# PIC32MZ1025W104132 register map
Vendor: Microchip
Registers are 32-bit, read-write, no defined reset value unless marked. A register's access mark holds for its fields unless they carry their own. Addresses are absolute, and some are shared; only a register's first bit layout is shown; [hi:lo] are bit positions; {n}, {i} and the like mark numbered series; 'fields as' and 'values as' point back to an identical list.

## ICAP1
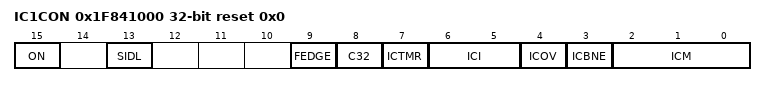
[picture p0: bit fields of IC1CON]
0x1F841000 IC1CON reset 0x0
  [15] ON, [13] SIDL, [9] FEDGE, [8] C32, [7] ICTMR, [6:5] ICI, [4] ICOV ro, [3] ICBNE ro, [2:0] ICM
0x1F841010 IC1BUF ro — (power-on value xxxxxxxxxxxxxxxxxxxxxxxxxxxxxxxx)

## ICAP2
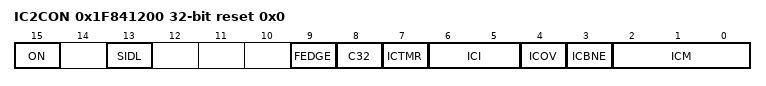
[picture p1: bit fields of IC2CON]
0x1F841200 IC2CON reset 0x0
  [15] ON, [13] SIDL, [9] FEDGE, [8] C32, [7] ICTMR, [6:5] ICI, [4] ICOV ro, [3] ICBNE ro, [2:0] ICM
0x1F841210 IC2BUF ro — (power-on value xxxxxxxxxxxxxxxxxxxxxxxxxxxxxxxx)

## ICAP3
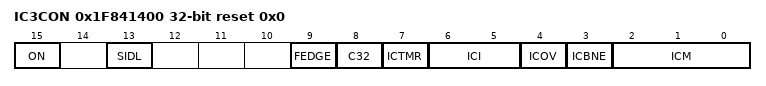
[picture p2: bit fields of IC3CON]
0x1F841400 IC3CON reset 0x0
  [15] ON, [13] SIDL, [9] FEDGE, [8] C32, [7] ICTMR, [6:5] ICI, [4] ICOV ro, [3] ICBNE ro, [2:0] ICM
0x1F841410 IC3BUF ro — (power-on value xxxxxxxxxxxxxxxxxxxxxxxxxxxxxxxx)

## ICAP4
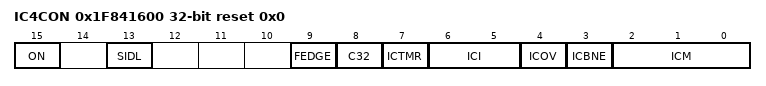
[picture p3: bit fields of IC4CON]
0x1F841600 IC4CON reset 0x0
  [15] ON, [13] SIDL, [9] FEDGE, [8] C32, [7] ICTMR, [6:5] ICI, [4] ICOV ro, [3] ICBNE ro, [2:0] ICM
0x1F841610 IC4BUF ro — (power-on value xxxxxxxxxxxxxxxxxxxxxxxxxxxxxxxx)

## OCMP1
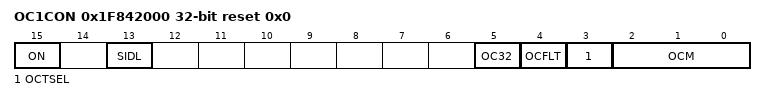
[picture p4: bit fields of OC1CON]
0x1F842000 OC1CON reset 0x0
  [15] ON, [13] SIDL, [5] OC32, [4] OCFLT ro, [3] OCTSEL, [2:0] OCM
0x1F842010 OC1R — (power-on value xxxxxxxxxxxxxxxxxxxxxxxxxxxxxxxx)
0x1F842020 OC1RS — (power-on value xxxxxxxxxxxxxxxxxxxxxxxxxxxxxxxx)

## OCMP2
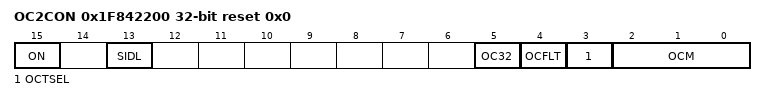
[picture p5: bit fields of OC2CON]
0x1F842200 OC2CON reset 0x0
  [15] ON, [13] SIDL, [5] OC32, [4] OCFLT ro, [3] OCTSEL, [2:0] OCM
0x1F842210 OC2R — (power-on value xxxxxxxxxxxxxxxxxxxxxxxxxxxxxxxx)
0x1F842220 OC2RS — (power-on value xxxxxxxxxxxxxxxxxxxxxxxxxxxxxxxx)

## OCMP3
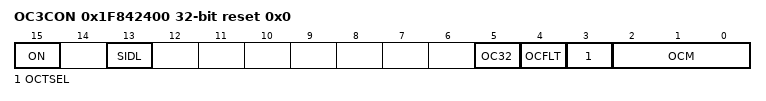
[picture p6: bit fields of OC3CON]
0x1F842400 OC3CON reset 0x0
  [15] ON, [13] SIDL, [5] OC32, [4] OCFLT ro, [3] OCTSEL, [2:0] OCM
0x1F842410 OC3R — (power-on value xxxxxxxxxxxxxxxxxxxxxxxxxxxxxxxx)
0x1F842420 OC3RS — (power-on value xxxxxxxxxxxxxxxxxxxxxxxxxxxxxxxx)

## OCMP4
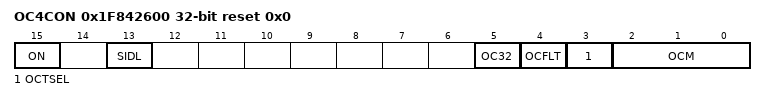
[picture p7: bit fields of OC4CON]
0x1F842600 OC4CON reset 0x0
  [15] ON, [13] SIDL, [5] OC32, [4] OCFLT ro, [3] OCTSEL, [2:0] OCM
0x1F842610 OC4R — (power-on value xxxxxxxxxxxxxxxxxxxxxxxxxxxxxxxx)
0x1F842620 OC4RS — (power-on value xxxxxxxxxxxxxxxxxxxxxxxxxxxxxxxx)

## USB1
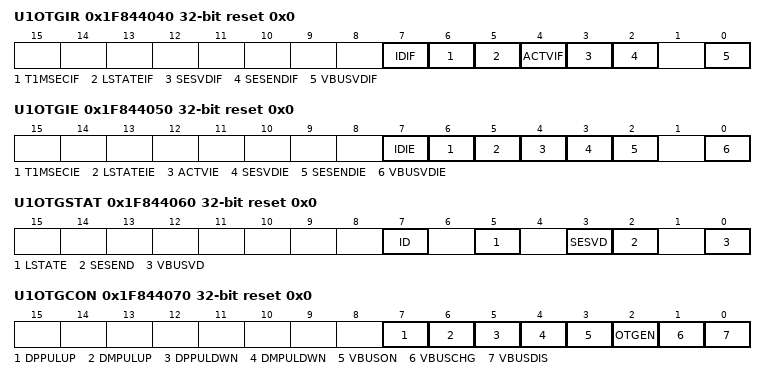
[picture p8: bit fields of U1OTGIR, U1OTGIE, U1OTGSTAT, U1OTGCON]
0x1F844040 U1OTGIR reset 0x0
  [7] IDIF, [6] T1MSECIF, [5] LSTATEIF, [4] ACTVIF, [3] SESVDIF, [2] SESENDIF, [0] VBUSVDIF
0x1F844050 U1OTGIE reset 0x0
  [7] IDIE, [6] T1MSECIE, [5] LSTATEIE, [4] ACTVIE, [3] SESVDIE, [2] SESENDIE, [0] VBUSVDIE
0x1F844060 U1OTGSTAT reset 0x0
  [7] ID, [5] LSTATE, [3] SESVD, [2] SESEND, [0] VBUSVD
0x1F844070 U1OTGCON reset 0x0
  [7] DPPULUP, [6] DMPULUP, [5] DPPULDWN, [4] DMPULDWN, [3] VBUSON, [2] OTGEN, [1] VBUSCHG, [0] VBUSDIS
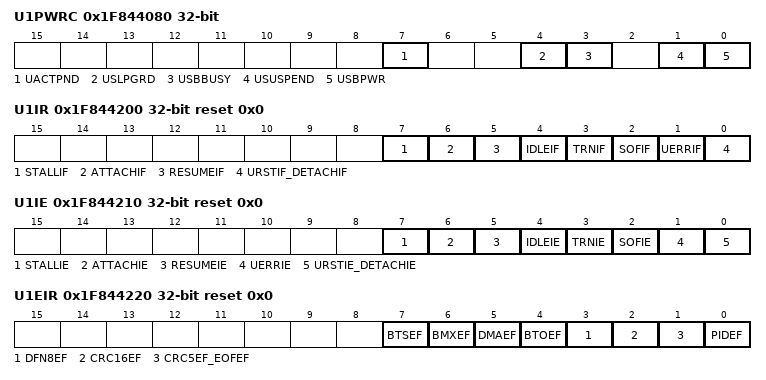
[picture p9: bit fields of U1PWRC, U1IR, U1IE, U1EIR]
0x1F844080 U1PWRC — (power-on value ------------------------0--0x-00)
  [7] UACTPND ro, [4] USLPGRD, [3] USBBUSY, [1] USUSPEND, [0] USBPWR
0x1F844200 U1IR reset 0x0
  [7] STALLIF, [6] ATTACHIF, [5] RESUMEIF, [4] IDLEIF, [3] TRNIF, [2] SOFIF, [1] UERRIF, [0] URSTIF_DETACHIF
0x1F844210 U1IE reset 0x0
  [7] STALLIE, [6] ATTACHIE, [5] RESUMEIE, [4] IDLEIE, [3] TRNIE, [2] SOFIE, [1] UERRIE, [0] URSTIE_DETACHIE
0x1F844220 U1EIR reset 0x0
  [7] BTSEF, [6] BMXEF, [5] DMAEF, [4] BTOEF, [3] DFN8EF, [2] CRC16EF, [1] CRC5EF_EOFEF, [0] PIDEF
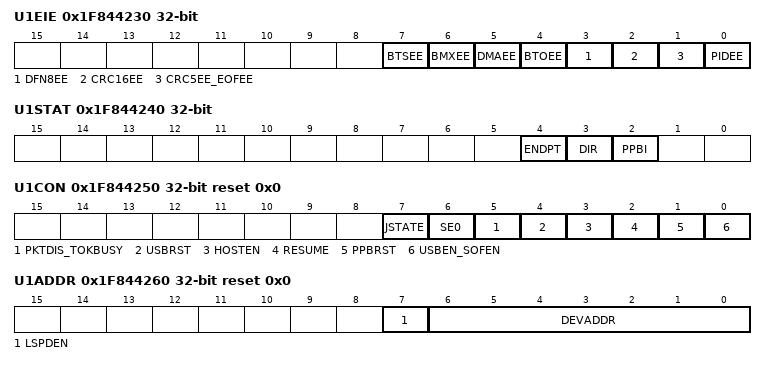
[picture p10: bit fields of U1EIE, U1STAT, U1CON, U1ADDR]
0x1F844230 U1EIE — (power-on value ------------------------0000000x)
  [7] BTSEE, [6] BMXEE, [5] DMAEE, [4] BTOEE, [3] DFN8EE, [2] CRC16EE, [1] CRC5EE_EOFEE, [0] PIDEE
0x1F844240 U1STAT ro
  [4] ENDPT, [3] DIR, [2] PPBI
0x1F844250 U1CON reset 0x0
  [7] JSTATE, [6] SE0, [5] PKTDIS_TOKBUSY, [4] USBRST, [3] HOSTEN, [2] RESUME, [1] PPBRST, [0] USBEN_SOFEN
0x1F844260 U1ADDR reset 0x0
  [7] LSPDEN, [6:0] DEVADDR
0x1F844270 U1BDTP1 reset 0x0
  [7:1] BDTPTRL
0x1F844280 U1FRML ro
  [7:0] FRML
0x1F844290 U1FRMH ro
  [2:0] FRMH
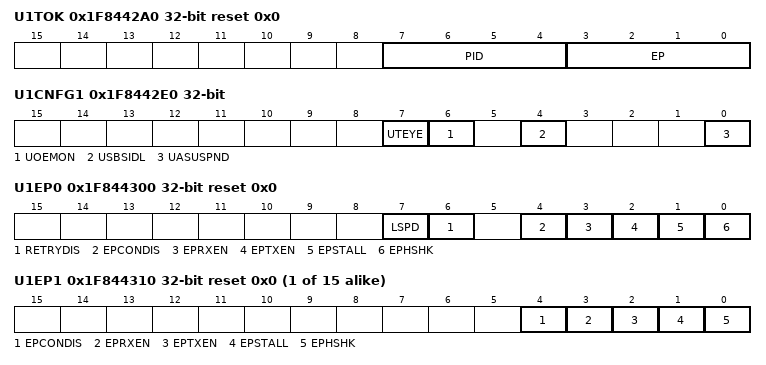
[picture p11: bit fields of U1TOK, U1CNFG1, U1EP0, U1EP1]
0x1F8442A0 U1TOK reset 0x0
  [7:4] PID, [3:0] EP
0x1F8442B0 U1SOF reset 0x0
  [7:0] CNT
0x1F8442C0 U1BDTP2 reset 0x0
  [7:0] BDTPTRH
0x1F8442D0 U1BDTP3 reset 0x0
  [7:0] BDTPTRU
0x1F8442E0 U1CNFG1 — (power-on value ------------------------xxxx-00x)
  [7] UTEYE, [6] UOEMON, [4] USBSIDL, [0] UASUSPND
0x1F844300 U1EP0 reset 0x0
  [7] LSPD, [6] RETRYDIS, [4] EPCONDIS, [3] EPRXEN, [2] EPTXEN, [1] EPSTALL, [0] EPHSHK
{0x1F844300+0x10*i} U1EP{i} reset 0x0 (i=1..15)
  [4] EPCONDIS, [3] EPRXEN, [2] EPTXEN, [1] EPSTALL, [0] EPHSHK

## RTCC
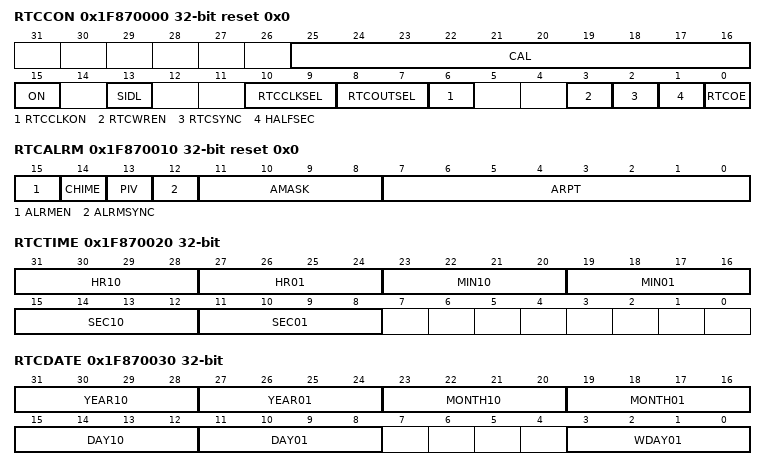
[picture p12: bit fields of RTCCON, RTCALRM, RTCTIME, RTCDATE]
0x1F870000 RTCCON reset 0x0
  [25:16] CAL, [15] ON, [13] SIDL, [10:9] RTCCLKSEL, [8:7] RTCOUTSEL, [6] RTCCLKON, [3] RTCWREN, [2] RTCSYNC ro, [1] HALFSEC ro, [0] RTCOE
0x1F870010 RTCALRM reset 0x0
  [15] ALRMEN, [14] CHIME, [13] PIV, [12] ALRMSYNC, [11:8] AMASK, [7:0] ARPT
0x1F870020 RTCTIME — (power-on value 000xxxxxxxxxxxxx0xxxxxxx--------)
  [31:28] HR10, [27:24] HR01, [23:20] MIN10, [19:16] MIN01, [15:12] SEC10, [11:8] SEC01
0x1F870030 RTCDATE — (power-on value xxxxxxxx000xxxxx00xxxxxx----0xxx)
  [31:28] YEAR10, [27:24] YEAR01, [23:20] MONTH10, [19:16] MONTH01, [15:12] DAY10, [11:8] DAY01, [3:0] WDAY01
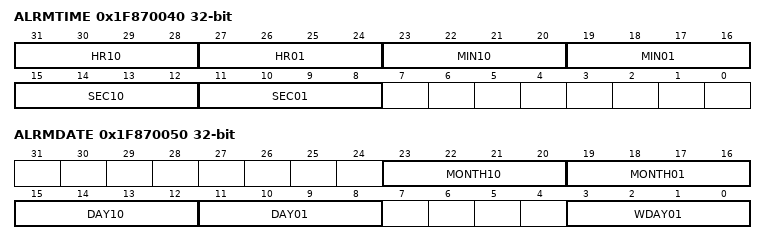
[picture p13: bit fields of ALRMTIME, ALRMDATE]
0x1F870040 ALRMTIME — (power-on value 000xxxxx0xxxxxxx0xxxxxxx--------)
  fields as RTCTIME
0x1F870050 ALRMDATE — (power-on value --------000xxxxx00xxxxxx----0xxx)
  [23:20] MONTH10, [19:16] MONTH01, [15:12] DAY10, [11:8] DAY01, [3:0] WDAY01

## CRYPTO
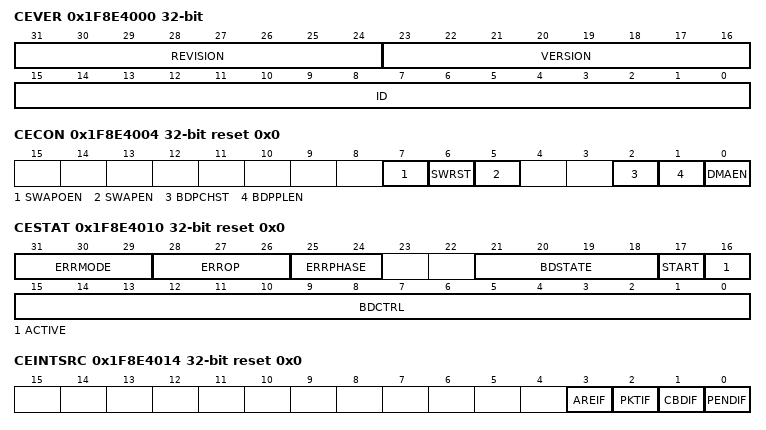
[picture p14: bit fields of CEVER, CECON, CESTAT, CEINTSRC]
0x1F8E4000 CEVER ro — (power-on value xxxxxxxxxxxxxxxxxxxxxxxxxxxxxxxx)
  [31:24] REVISION, [23:16] VERSION, [15:0] ID
0x1F8E4004 CECON reset 0x0
  [7] SWAPOEN, [6] SWRST, [5] SWAPEN, [2] BDPCHST, [1] BDPPLEN, [0] DMAEN
0x1F8E4008 CEBDADDR ro reset 0x0
  [31:0] BDPADDR
0x1F8E400C CEBDPADDR ro reset 0x0
  [31:0] BASEADDR
0x1F8E4010 CESTAT ro reset 0x0
  [31:29] ERRMODE, [28:26] ERROP, [25:24] ERRPHASE, [21:18] BDSTATE, [17] START, [16] ACTIVE, [15:0] BDCTRL
0x1F8E4014 CEINTSRC ro reset 0x0
  [3] AREIF, [2] PKTIF, [1] CBDIF, [0] PENDIF
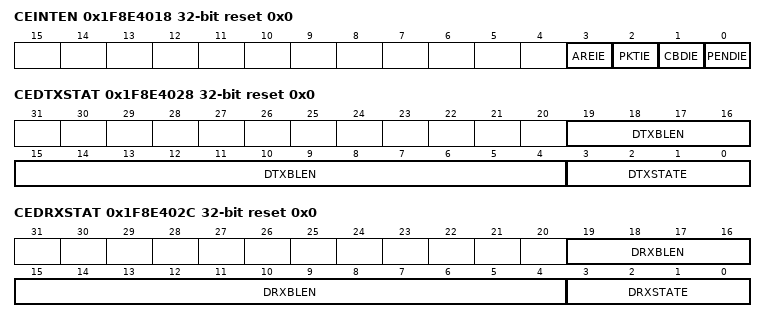
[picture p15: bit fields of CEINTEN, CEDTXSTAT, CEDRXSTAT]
0x1F8E4018 CEINTEN reset 0x0
  [3] AREIE, [2] PKTIE, [1] CBDIE, [0] PENDIE
0x1F8E401C CEPOLLCON reset 0x0
  [15:0] BDPPLCON
0x1F8E4020 CEHDLEN reset 0x0
  [7:0] HDRLEN
0x1F8E4024 CETRLLEN reset 0x0
  [7:0] TRLRLEN
0x1F8E4028 CEDTXSTAT reset 0x0
  [19:4] DTXBLEN, [3:0] DTXSTATE
0x1F8E402C CEDRXSTAT reset 0x0
  [19:4] DRXBLEN, [3:0] DRXSTATE
0x1F8E4030 CEDCRYPTOADDR ro reset 0x0
  [3:0] CRYPTOADDR
0x1F8E4034 CEDHASHADDR ro reset 0x0
  [3:0] HASHADDR
0x1F8E4038 CEDTXADDR ro reset 0x0
  [1:0] TXDADDR
0x1F8E403C CEDML0ADDR ro reset 0x0
  [31:0] ML0ADDR
0x1F8E4040 CEDML1ADDR ro reset 0x0
  [31:0] ML1ADDR
0x1F8E4044 CEDOL0ADDR ro reset 0x0
  [31:0] OL0ADDR
0x1F8E4048 CEDCSTADDDR ro reset 0x0
  [3:0] CSTATEADDR
0x1F8E404C CEDMTSKADDR ro — (power-on value ------------------------------xx)
  [1:0] MTASKADDR
0x1F8E4050 CEDSACON ro reset 0x0
  [31:0] SACON
0x1F8E4054 CEDCSTATE ro reset 0x0
  [3:0] CSTATE
0x1F8E4058 CEDTXBCNT ro reset 0x0
  [4:0] CTXBCNT
0x1F8E405C CEDRXBCNT ro reset 0x0
  [6:0] DRXBCNT

## RNG
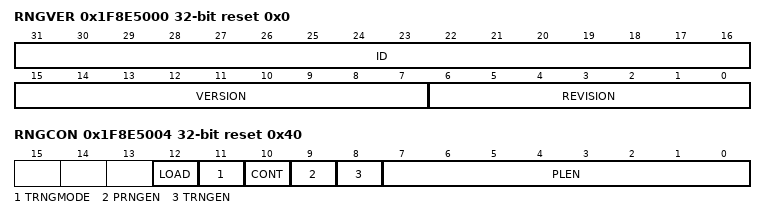
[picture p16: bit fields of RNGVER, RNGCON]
0x1F8E5000 RNGVER ro reset 0x0
  [31:16] ID, [15:7] VERSION, [6:0] REVISION
0x1F8E5004 RNGCON reset 0x40
  [12] LOAD, [11] TRNGMODE, [10] CONT, [9] PRNGEN, [8] TRNGEN, [7:0] PLEN
0x1F8E5008 RNGPOLY1 reset 0xFFFF0000
  [31:0] POLY
0x1F8E500C RNGPOLY2 reset 0xFFFF0000
  [31:0] POLY
0x1F8E5010 RNGNUMGEN1 reset 0xFFFFFFFF
  [31:0] RNG
0x1F8E5014 RNGNUMGEN2 reset 0xFFFFFFFF
  [31:0] RNG
0x1F8E5018 RNGSEED1 ro reset 0x0
  [31:0] SEED
0x1F8E501C RNGSEED2 ro reset 0x0
  [31:0] SEED
0x1F8E5020 RNGCNT reset 0x0
  [6:0] RCNT
